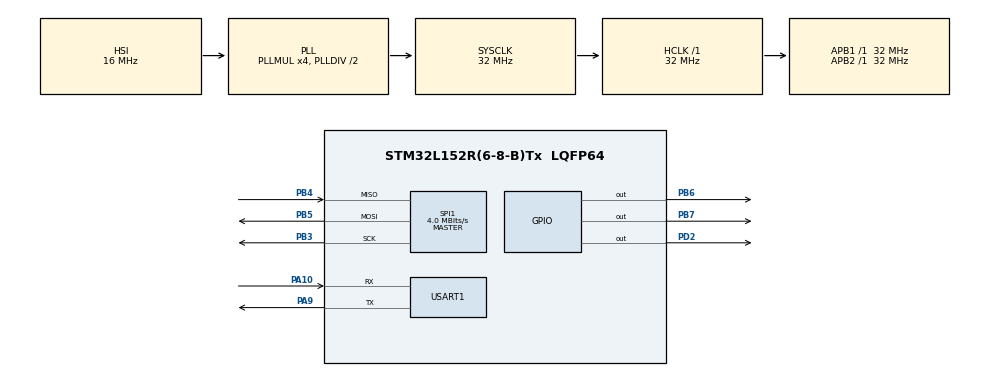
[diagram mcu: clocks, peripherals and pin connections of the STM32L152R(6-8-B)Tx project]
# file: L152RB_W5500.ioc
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Mcu.Family=STM32L1
Mcu.Name=STM32L152R(6-8-B)Tx
Mcu.Package=LQFP64
NVIC.PriorityGroup=NVIC_PRIORITYGROUP_4
NVIC.SPI1_IRQn=true\:0\:0\:false\:false\:true\:true\:true
NVIC.USART1_IRQn=true\:0\:0\:false\:false\:true\:true\:true
PA10.Mode=Asynchronous
PA10.Signal=USART1_RX
PA9.Mode=Asynchronous
PA9.Signal=USART1_TX
PB3.Mode=Full_Duplex_Master
PB3.Signal=SPI1_SCK
PB4.Mode=Full_Duplex_Master
PB4.Signal=SPI1_MISO
PB5.Mode=Full_Duplex_Master
PB5.Signal=SPI1_MOSI
PB6.Signal=GPIO_Output
PB7.Signal=GPIO_Output
PD2.GPIO_Speed=GPIO_SPEED_FREQ_VERY_HIGH
PD2.PinState=GPIO_PIN_SET
PD2.Signal=GPIO_Output
ProjectManager.HeapSize=0x200
ProjectManager.StackSize=0x400
ProjectManager.TargetToolchain=STM32CubeIDE
RCC.48MHZClocksFreq_Value=32000000
RCC.AHBFreq_Value=32000000
RCC.APB1Freq_Value=32000000
RCC.APB1TimFreq_Value=32000000
RCC.APB2Freq_Value=32000000
RCC.APB2TimFreq_Value=32000000
RCC.HCLKFreq_Value=32000000
RCC.HSE_VALUE=24000000
RCC.HSI_VALUE=16000000
RCC.LSE_VALUE=32768
RCC.MSI_VALUE=2097000
RCC.PLLMUL=RCC_PLL_MUL4
RCC.SYSCLKFreq_VALUE=32000000
RCC.SYSCLKSource=RCC_SYSCLKSOURCE_PLLCLK
RCC.VCOOutputFreq_Value=64000000
SPI1.BaudRatePrescaler=SPI_BAUDRATEPRESCALER_8
SPI1.CalculateBaudRate=4.0 MBits/s
SPI1.Direction=SPI_DIRECTION_2LINES
SPI1.Mode=SPI_MODE_MASTER
SPI1.VirtualType=VM_MASTER
USART1.VirtualMode=VM_ASYNC
board=custom

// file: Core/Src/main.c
/* USER CODE BEGIN Header */
/**
  ******************************************************************************
  * @file           : main.c
  * @brief          : Main program body
  ******************************************************************************
  * @attention
  *
  * <h2><center>&copy; Copyright (c) 2020 STMicroelectronics.
  * All rights reserved.</center></h2>
  *
  * This software component is licensed by ST under BSD 3-Clause license,
  * the "License"; You may not use this file except in compliance with the
  * License. You may obtain a copy of the License at:
  *                        opensource.org/licenses/BSD-3-Clause
  *
  ******************************************************************************
  */
/* USER CODE END Header */
#include "main.h"
#include "wizchip_conf.h"
#include "socket.h"
#include "loopback.h"

SPI_HandleTypeDef hspi1;

UART_HandleTypeDef huart1;

void SystemClock_Config(void);
static void MX_GPIO_Init(void);
static void MX_SPI1_Init(void);
static void MX_USART1_UART_Init(void);

void cs_sel() {
	HAL_GPIO_WritePin(GPIOD, GPIO_PIN_2, GPIO_PIN_RESET); //CS LOW
}

void cs_desel() {
	HAL_GPIO_WritePin(GPIOD, GPIO_PIN_2, GPIO_PIN_SET); //CS HIGH
}

uint8_t spi_rb(void) {
	uint8_t rbuf;
	HAL_SPI_Receive(&hspi1, &rbuf, 1, 0xFFFFFFFF);
	return rbuf;
}

void spi_wb(uint8_t b) {
	HAL_SPI_Transmit(&hspi1, &b, 1, 0xFFFFFFFF);
}

int main(void)
{
  /* USER CODE BEGIN 1 */
  uint8_t retVal, sockStatus;
  int16_t rcvLen;
  uint8_t rcvBuf[20], bufSize[] = {2, 2, 2, 2};
  /* USER CODE END 1 */

  /* MCU Configuration--------------------------------------------------------*/

  /* Reset of all peripherals, Initializes the Flash interface and the Systick. */
  HAL_Init();

  /* Configure the system clock */
  SystemClock_Config();

  /* Initialize all configured peripherals */
  MX_GPIO_Init();
  MX_SPI1_Init();
  MX_USART1_UART_Init();
  /* USER CODE BEGIN 2 */
  //PRINT_HEADER();

  reg_wizchip_cs_cbfunc(cs_sel, cs_desel);
  reg_wizchip_spi_cbfunc(spi_rb, spi_wb);

  wizchip_init(bufSize, bufSize);
  wiz_NetInfo netInfo = { .mac 	= {0x00, 0x08, 0xdc, 0xab, 0xcd, 0xef},	// Mac address
                          .ip 	= {192, 168, 2, 192},					// IP address
                          .sn 	= {255, 255, 255, 0},					// Subnet mask
                          .gw 	= {192, 168, 2, 1}};					// Gateway address
  wizchip_setnetinfo(&netInfo);
  wizchip_getnetinfo(&netInfo);
  //PRINT_NETINFO(netInfo);

  while (1)
  {
    /* USER CODE END WHILE */

    /* USER CODE BEGIN 3 */
  }
}

void SystemClock_Config(void)
{
  RCC_OscInitTypeDef RCC_OscInitStruct = {0};
  RCC_ClkInitTypeDef RCC_ClkInitStruct = {0};

  /** Configure the main internal regulator output voltage
  */
  __HAL_PWR_VOLTAGESCALING_CONFIG(PWR_REGULATOR_VOLTAGE_SCALE1);
  /** Initializes the RCC Oscillators according to the specified parameters
  * in the RCC_OscInitTypeDef structure.
  */
  RCC_OscInitStruct.OscillatorType = RCC_OSCILLATORTYPE_HSI;
  RCC_OscInitStruct.HSIState = RCC_HSI_ON;
  RCC_OscInitStruct.HSICalibrationValue = RCC_HSICALIBRATION_DEFAULT;
  RCC_OscInitStruct.PLL.PLLState = RCC_PLL_ON;
  RCC_OscInitStruct.PLL.PLLSource = RCC_PLLSOURCE_HSI;
  RCC_OscInitStruct.PLL.PLLMUL = RCC_PLL_MUL4;
  RCC_OscInitStruct.PLL.PLLDIV = RCC_PLL_DIV2;
  if (HAL_RCC_OscConfig(&RCC_OscInitStruct) != HAL_OK)
  {
    Error_Handler();
  }
  /** Initializes the CPU, AHB and APB buses clocks
  */
  RCC_ClkInitStruct.ClockType = RCC_CLOCKTYPE_HCLK|RCC_CLOCKTYPE_SYSCLK
                              |RCC_CLOCKTYPE_PCLK1|RCC_CLOCKTYPE_PCLK2;
  RCC_ClkInitStruct.SYSCLKSource = RCC_SYSCLKSOURCE_PLLCLK;
  RCC_ClkInitStruct.AHBCLKDivider = RCC_SYSCLK_DIV1;
  RCC_ClkInitStruct.APB1CLKDivider = RCC_HCLK_DIV1;
  RCC_ClkInitStruct.APB2CLKDivider = RCC_HCLK_DIV1;

  if (HAL_RCC_ClockConfig(&RCC_ClkInitStruct, FLASH_LATENCY_1) != HAL_OK)
  {
    Error_Handler();
  }
}

static void MX_SPI1_Init(void)
{

  /* SPI1 parameter configuration*/
  hspi1.Instance = SPI1;
  hspi1.Init.Mode = SPI_MODE_MASTER;
  hspi1.Init.Direction = SPI_DIRECTION_2LINES;
  hspi1.Init.DataSize = SPI_DATASIZE_8BIT;
  hspi1.Init.CLKPolarity = SPI_POLARITY_LOW;
  hspi1.Init.CLKPhase = SPI_PHASE_1EDGE;
  hspi1.Init.NSS = SPI_NSS_SOFT;
  hspi1.Init.BaudRatePrescaler = SPI_BAUDRATEPRESCALER_8;
  hspi1.Init.FirstBit = SPI_FIRSTBIT_MSB;
  hspi1.Init.TIMode = SPI_TIMODE_DISABLE;
  hspi1.Init.CRCCalculation = SPI_CRCCALCULATION_DISABLE;
  hspi1.Init.CRCPolynomial = 10;
  if (HAL_SPI_Init(&hspi1) != HAL_OK)
  {
    Error_Handler();
  }

}

static void MX_USART1_UART_Init(void)
{

  huart1.Instance = USART1;
  huart1.Init.BaudRate = 115200;
  huart1.Init.WordLength = UART_WORDLENGTH_8B;
  huart1.Init.StopBits = UART_STOPBITS_1;
  huart1.Init.Parity = UART_PARITY_NONE;
  huart1.Init.Mode = UART_MODE_TX_RX;
  huart1.Init.HwFlowCtl = UART_HWCONTROL_NONE;
  huart1.Init.OverSampling = UART_OVERSAMPLING_16;
  if (HAL_UART_Init(&huart1) != HAL_OK)
  {
    Error_Handler();
  }

}

static void MX_GPIO_Init(void)
{
  GPIO_InitTypeDef GPIO_InitStruct = {0};

  /* GPIO Ports Clock Enable */
  __HAL_RCC_GPIOA_CLK_ENABLE();
  __HAL_RCC_GPIOD_CLK_ENABLE();
  __HAL_RCC_GPIOB_CLK_ENABLE();

  /*Configure GPIO pin Output Level */
  HAL_GPIO_WritePin(GPIOD, GPIO_PIN_2, GPIO_PIN_SET);

  /*Configure GPIO pin Output Level */
  HAL_GPIO_WritePin(GPIOB, GPIO_PIN_6|GPIO_PIN_7, GPIO_PIN_RESET);

  /*Configure GPIO pin : PD2 */
  GPIO_InitStruct.Pin = GPIO_PIN_2;
  GPIO_InitStruct.Mode = GPIO_MODE_OUTPUT_PP;
  GPIO_InitStruct.Pull = GPIO_NOPULL;
  GPIO_InitStruct.Speed = GPIO_SPEED_FREQ_VERY_HIGH;
  HAL_GPIO_Init(GPIOD, &GPIO_InitStruct);

  /*Configure GPIO pins : PB6 PB7 */
  GPIO_InitStruct.Pin = GPIO_PIN_6|GPIO_PIN_7;
  GPIO_InitStruct.Mode = GPIO_MODE_OUTPUT_PP;
  GPIO_InitStruct.Pull = GPIO_NOPULL;
  GPIO_InitStruct.Speed = GPIO_SPEED_FREQ_LOW;
  HAL_GPIO_Init(GPIOB, &GPIO_InitStruct);

}

void Error_Handler(void)
{
}

/************************ (C) COPYRIGHT STMicroelectronics *****END OF FILE****/
